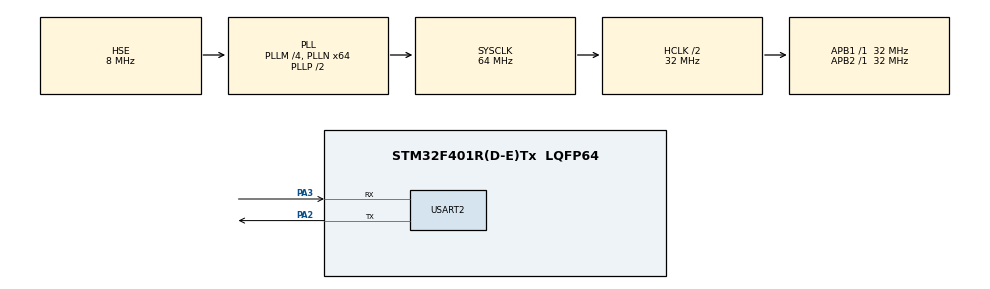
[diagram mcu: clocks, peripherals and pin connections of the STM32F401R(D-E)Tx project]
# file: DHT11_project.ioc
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Mcu.Family=STM32F4
Mcu.Name=STM32F401R(D-E)Tx
Mcu.Package=LQFP64
NVIC.PriorityGroup=NVIC_PRIORITYGROUP_4
PA13.Mode=Serial_Wire
PA13.Signal=SYS_JTMS-SWDIO
PA14.Mode=Serial_Wire
PA14.Signal=SYS_JTCK-SWCLK
PA2.Mode=Asynchronous
PA2.Signal=USART2_TX
PA3.Mode=Asynchronous
PA3.Signal=USART2_RX
PH0\ -\ OSC_IN.Mode=HSE-External-Oscillator
PH0\ -\ OSC_IN.Signal=RCC_OSC_IN
PH1\ -\ OSC_OUT.Mode=HSE-External-Oscillator
PH1\ -\ OSC_OUT.Signal=RCC_OSC_OUT
ProjectManager.HeapSize=0x200
ProjectManager.StackSize=0x400
ProjectManager.TargetToolchain=STM32CubeIDE
RCC.48MHZClocksFreq_Value=32000000
RCC.AHBCLKDivider=RCC_SYSCLK_DIV2
RCC.AHBFreq_Value=32000000
RCC.APB1Freq_Value=32000000
RCC.APB1TimFreq_Value=32000000
RCC.APB2Freq_Value=32000000
RCC.APB2TimFreq_Value=32000000
RCC.CortexFreq_Value=32000000
RCC.HCLKFreq_Value=32000000
RCC.HSE_VALUE=8000000
RCC.HSI_VALUE=16000000
RCC.LSE_VALUE=32768
RCC.PLLM=4
RCC.PLLN=64
RCC.PLLSourceVirtual=RCC_PLLSOURCE_HSE
RCC.SYSCLKFreq_VALUE=64000000
RCC.SYSCLKSource=RCC_SYSCLKSOURCE_PLLCLK
RCC.VCOOutputFreq_Value=128000000
USART2.VirtualMode=VM_ASYNC
VP_TIM3_VS_ClockSourceINT.Mode=Internal
board=custom

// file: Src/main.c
/* USER CODE BEGIN Header */
/**
  ******************************************************************************
  * @file           : main.c
  * @brief          : Main program body
  ******************************************************************************
  * @attention
  *
  * <h2><center>&copy; Copyright (c) 2021 STMicroelectronics.
  * All rights reserved.</center></h2>
  *
  * This software component is licensed by ST under BSD 3-Clause license,
  * the "License"; You may not use this file except in compliance with the
  * License. You may obtain a copy of the License at:
  *                        opensource.org/licenses/BSD-3-Clause
  *
  ******************************************************************************
  */
/* USER CODE END Header */
#include "main.h"

/* USER CODE BEGIN Includes */
#include "DHT11.h"

/* USER CODE END Includes */

TIM_HandleTypeDef htim3;

UART_HandleTypeDef huart2;

void SystemClock_Config(void);
static void MX_GPIO_Init(void);
static void MX_TIM3_Init(void);
static void MX_USART2_UART_Init(void);

/* USER CODE BEGIN 0 */
uint8_t Rh_byte1, Rh_byte2, Temp_byte1, Temp_byte2,sum ,presense;

float Temp=0;
float humidity =0;

float buff[100]={0};

/* USER CODE END 0 */

int main(void)
{

  /* MCU Configuration--------------------------------------------------------*/

  /* Reset of all peripherals, Initializes the Flash interface and the Systick. */
  HAL_Init();

  /* Configure the system clock */
  SystemClock_Config();

  /* Initialize all configured peripherals */
  MX_GPIO_Init();
  MX_TIM3_Init();
  MX_USART2_UART_Init();
  /* USER CODE BEGIN 2 */
HAL_TIM_Base_Start(&htim3);
  /* USER CODE END 2 */

  /* Infinite loop */
  while (1)
  {

    /* USER CODE BEGIN 3 */
	  DHT11Start();
	 	  presense = DHTResponse();
	 	  Rh_byte1 = DHTRead();
	 	  Rh_byte2 = DHTRead();
	 	  Temp_byte1 = DHTRead();
	 	  Temp_byte2 = DHTRead();
	 	  sum = DHTRead();

	 	  Temp = (float)Temp_byte1;
	 	  humidity = (float)Rh_byte1;

	 	  sprintf(buff," Temp= %d,  Humidity=%d\r\n ", Temp, humidity);

	 	  HAL_UART_Transmit(&huart2, &buff, 100, HAL_MAX_DELAY);
  }
  /* USER CODE END 3 */
}

void SystemClock_Config(void)
{
  RCC_OscInitTypeDef RCC_OscInitStruct = {0};
  RCC_ClkInitTypeDef RCC_ClkInitStruct = {0};

  /** Configure the main internal regulator output voltage
  */
  __HAL_RCC_PWR_CLK_ENABLE();
  __HAL_PWR_VOLTAGESCALING_CONFIG(PWR_REGULATOR_VOLTAGE_SCALE2);
  /** Initializes the RCC Oscillators according to the specified parameters
  * in the RCC_OscInitTypeDef structure.
  */
  RCC_OscInitStruct.OscillatorType = RCC_OSCILLATORTYPE_HSE;
  RCC_OscInitStruct.HSEState = RCC_HSE_ON;
  RCC_OscInitStruct.PLL.PLLState = RCC_PLL_ON;
  RCC_OscInitStruct.PLL.PLLSource = RCC_PLLSOURCE_HSE;
  RCC_OscInitStruct.PLL.PLLM = 4;
  RCC_OscInitStruct.PLL.PLLN = 64;
  RCC_OscInitStruct.PLL.PLLP = RCC_PLLP_DIV2;
  RCC_OscInitStruct.PLL.PLLQ = 4;
  if (HAL_RCC_OscConfig(&RCC_OscInitStruct) != HAL_OK)
  {
    Error_Handler();
  }
  /** Initializes the CPU, AHB and APB buses clocks
  */
  RCC_ClkInitStruct.ClockType = RCC_CLOCKTYPE_HCLK|RCC_CLOCKTYPE_SYSCLK
                              |RCC_CLOCKTYPE_PCLK1|RCC_CLOCKTYPE_PCLK2;
  RCC_ClkInitStruct.SYSCLKSource = RCC_SYSCLKSOURCE_PLLCLK;
  RCC_ClkInitStruct.AHBCLKDivider = RCC_SYSCLK_DIV2;
  RCC_ClkInitStruct.APB1CLKDivider = RCC_HCLK_DIV1;
  RCC_ClkInitStruct.APB2CLKDivider = RCC_HCLK_DIV1;

  if (HAL_RCC_ClockConfig(&RCC_ClkInitStruct, FLASH_LATENCY_1) != HAL_OK)
  {
    Error_Handler();
  }
}

static void MX_TIM3_Init(void)
{

  TIM_ClockConfigTypeDef sClockSourceConfig = {0};
  TIM_MasterConfigTypeDef sMasterConfig = {0};

  htim3.Instance = TIM3;
  htim3.Init.Prescaler = 0;
  htim3.Init.CounterMode = TIM_COUNTERMODE_UP;
  htim3.Init.Period = 65535;
  htim3.Init.ClockDivision = TIM_CLOCKDIVISION_DIV1;
  htim3.Init.AutoReloadPreload = TIM_AUTORELOAD_PRELOAD_DISABLE;
  if (HAL_TIM_Base_Init(&htim3) != HAL_OK)
  {
    Error_Handler();
  }
  sClockSourceConfig.ClockSource = TIM_CLOCKSOURCE_INTERNAL;
  if (HAL_TIM_ConfigClockSource(&htim3, &sClockSourceConfig) != HAL_OK)
  {
    Error_Handler();
  }
  sMasterConfig.MasterOutputTrigger = TIM_TRGO_RESET;
  sMasterConfig.MasterSlaveMode = TIM_MASTERSLAVEMODE_DISABLE;
  if (HAL_TIMEx_MasterConfigSynchronization(&htim3, &sMasterConfig) != HAL_OK)
  {
    Error_Handler();
  }

}

static void MX_USART2_UART_Init(void)
{

  huart2.Instance = USART2;
  huart2.Init.BaudRate = 115200;
  huart2.Init.WordLength = UART_WORDLENGTH_8B;
  huart2.Init.StopBits = UART_STOPBITS_1;
  huart2.Init.Parity = UART_PARITY_NONE;
  huart2.Init.Mode = UART_MODE_TX_RX;
  huart2.Init.HwFlowCtl = UART_HWCONTROL_NONE;
  huart2.Init.OverSampling = UART_OVERSAMPLING_16;
  if (HAL_UART_Init(&huart2) != HAL_OK)
  {
    Error_Handler();
  }

}

static void MX_GPIO_Init(void)
{

  /* GPIO Ports Clock Enable */
  __HAL_RCC_GPIOH_CLK_ENABLE();
  __HAL_RCC_GPIOA_CLK_ENABLE();

}

void Error_Handler(void)
{
  __disable_irq();
  while (1)
  {
  }
}

/************************ (C) COPYRIGHT STMicroelectronics *****END OF FILE****/
